# STM32H730xxQ register map
File version: 1.0
Registers are 32-bit, read-write, reset 0x0 unless marked. A register's access mark holds for its fields unless they carry their own. Offsets are from the block's base; [hi:lo] are bit positions; {n}, {i} and the like mark numbered series; 'fields as' and 'values as' point back to an identical list.

## FMC_Bank1E_R — Flexible Memory Controller Bank1E
Base 0x52004104
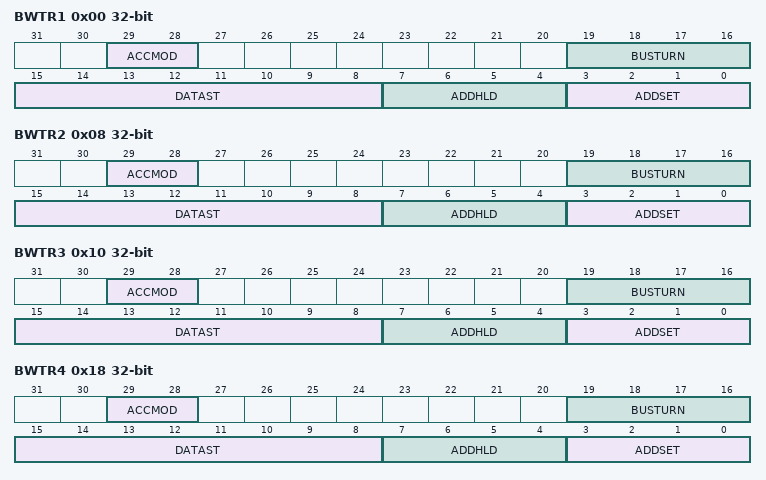
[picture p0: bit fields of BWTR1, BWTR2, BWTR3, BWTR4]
0x00 BWTR1 — NOR/PSRAM write timing registers
  [29:28] ACCMOD — ACCMOD[1:0] bits (Access mode)
  [19:16] BUSTURN — BUSTURN[3:0] bits (Bus turnaround phase duration)
  [15:8] DATAST — DATAST [3:0] bits (Data-phase duration)
  [7:4] ADDHLD — ADDHLD[3:0] bits (Address-hold phase duration)
  [3:0] ADDSET — ADDSET[3:0] bits (Address setup phase duration)
0x08 BWTR2 — NOR/PSRAM write timing registers
  fields as BWTR1
0x10 BWTR3 — NOR/PSRAM write timing registers
  fields as BWTR1
0x18 BWTR4 — NOR/PSRAM write timing registers
  fields as BWTR1

## FMC_Bank5_6_R — Flexible Memory Controller Bank5 and 6
Base 0x52004140
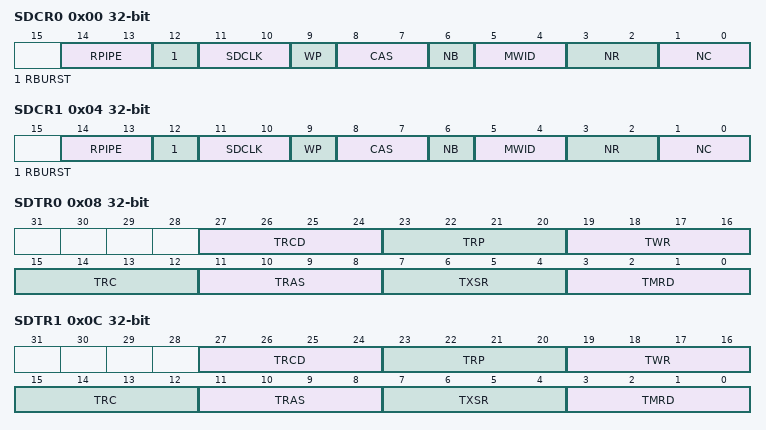
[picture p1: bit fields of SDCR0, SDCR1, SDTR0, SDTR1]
0x00 SDCR0 — SDRAM Control registers
  [14:13] RPIPE — Write protection
  [12] RBURST — Read burst
  [11:10] SDCLK — SDRAM clock configuration
  [9] WP — Write protection
  [8:7] CAS — CAS[1:0] bits (CAS latency)
  [6] NB — Number of internal bank
  [5:4] MWID — NR[1:0] bits (Number of row bits)
  [3:2] NR — NR[1:0] bits (Number of row bits)
  [1:0] NC — NC[1:0] bits (Number of column bits)
0x04 SDCR1 — SDRAM Control registers
  fields as SDCR0
0x08 SDTR0 — SDRAM Timing registers
  [27:24] TRCD — TRP[2:0] bits (Row to column delay)
  [23:20] TRP — TRP[2:0] bits (Row precharge delay)
  [19:16] TWR — TRC[2:0] bits (Write recovery delay)
  [15:12] TRC — TRC[2:0] bits (Row cycle delay)
  [11:8] TRAS — TRAS[3:0] bits (Self refresh time)
  [7:4] TXSR — TXSR[3:0] bits (Exit self refresh)
  [3:0] TMRD — TMRD[3:0] bits (Load mode register to active)
0x0C SDTR1 — SDRAM Timing registers
  fields as SDTR0
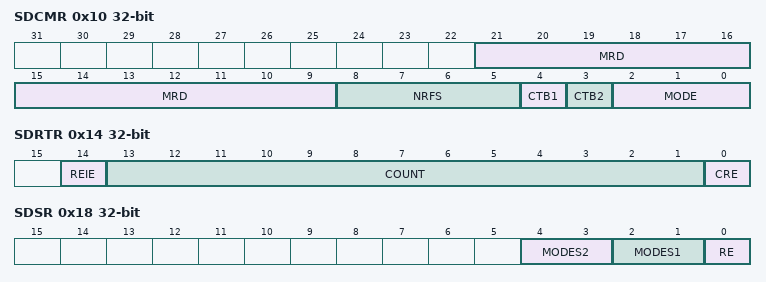
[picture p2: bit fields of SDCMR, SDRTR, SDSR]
0x10 SDCMR — SDRAM Command Mode register
  [21:9] MRD — MRD[12:0] bits (Mode register definition)
  [8:5] NRFS — NRFS[3:0] bits (Number of auto-refresh)
  [4] CTB1 — Command target 1
  [3] CTB2 — Command target 2
  [2:0] MODE — MODE[2:0] bits (Command mode)
0x14 SDRTR — SDRAM Refresh Timer register
  [14] REIE — RES interrupt enable
  [13:1] COUNT — COUNT[12:0] bits (Refresh timer count)
  [0] CRE — Clear refresh error flag
0x18 SDSR — SDRAM Status register
  [4:3] MODES2 — MODES2[1:0]bits (Status mode for bank 2)
  [2:1] MODES1 — MODES1[1:0]bits (Status mode for bank 1)
  [0] RE — Refresh error flag

## OCTOSPIM — OCTO Serial Peripheral Interface IO Manager
Base 0x5200B400
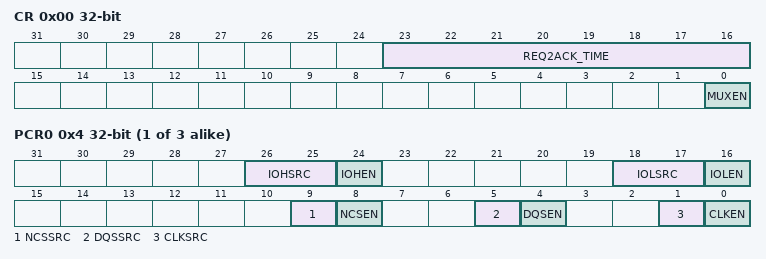
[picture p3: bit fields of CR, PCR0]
0x00 CR — OCTOSPI IO Manager Control register
  [23:16] REQ2ACK_TIME — REQ to ACK time
  [0] MUXEN — Multiplexed mode enable
{0x4+4i} PCR{i} (i=0..2) — OCTOSPI IO Manager Port[1:3] Configuration register
  [26:25] IOHSRC — IO[7:4] Source for Port n
  [24] IOHEN — IO[7:4] Enable for Port n
  [18:17] IOLSRC — IO[3:0] Source for Port n
  [16] IOLEN — IO[3:0] Enable for Port n
  [9] NCSSRC — nCS Source for Port n
  [8] NCSEN — nCS Enable for Port n
  [5] DQSSRC — DQS Source for Port n
  [4] DQSEN — DQS Enable for Port n
  [1] CLKSRC — CLK/CLKn Source for Port n
  [0] CLKEN — CLK/CLKn Enable for Port n

## OTFDEC1
Base 0x5200B800
Same registers: OTFDEC2 0x5200BC00
0x00 CR
  [0] ENC — Encryption mode bit
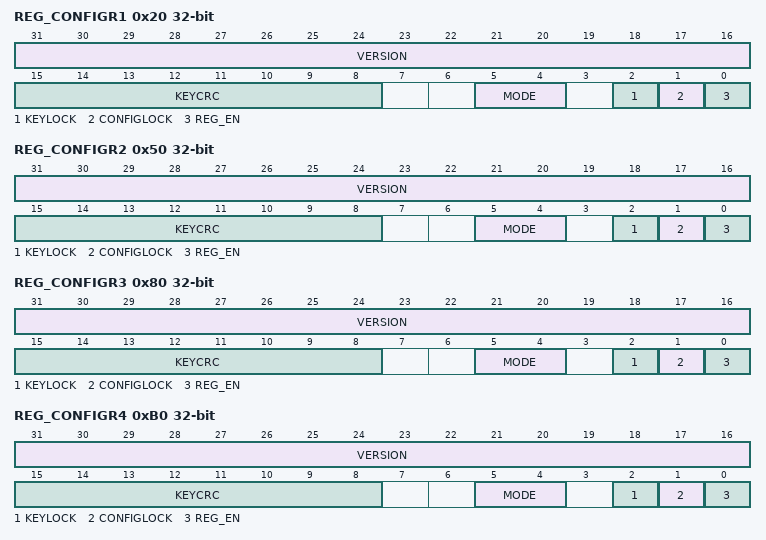
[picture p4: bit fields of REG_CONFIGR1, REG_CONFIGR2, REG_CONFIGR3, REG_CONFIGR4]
0x20 REG_CONFIGR1
  [31:16] VERSION — Region firmware version
  [15:8] KEYCRC — Region key 8-bit CRC
  [5:4] MODE — Region operating mode
  [2] KEYLOCK — Region key lock
  [1] CONFIGLOCK — Region config lock
  [0] REG_EN — Region on-the-fly decryption enable
0x24 REG_START_ADDR1
  [31:0] REG_START_ADDR — Region AHB start address
0x28 REG_END_ADDR1
  [31:0] REG_END_ADDR — Region AHB end address
0x2C REG_NONCER01
  [31:0] REG_NONCER0 — Region Nonce Register (LSB nonce[31:0])
0x30 REG_NONCER1
  [31:0] REG_NONCER1 — Region Nonce Register (MSB nonce[63:32])
{0x4+0x30*i} REG_KEYR{i:02} (i=1..4)
  [31:0] REG_KEYR0 — Region Key Register (LSB key[31:0])
{0x4+0x34*i} REG_KEYR{i} (i=1..3)
  [31:0] REG_KEYR{i} — Region Key Register (key[{32i+31}:{32i}])
0x3C REG_KEYR21
  [31:0] REG_KEYR2 — Region Key Register (key[95:64])
0x40 REG_KEYR31
  [31:0] REG_KEYR3 — Region Key Register (key[127:96])
0x50 REG_CONFIGR2
  fields as REG_CONFIGR1
0x54 REG_START_ADDR2
  [31:0] REG_START_ADDR — Region AHB start address
0x58 REG_END_ADDR2
  [31:0] REG_END_ADDR — Region AHB end address
0x5C REG_NONCER02
  [31:0] REG_NONCER0 — Region Nonce Register (LSB nonce[31:0])
0x60 REG_NONCER12
  [31:0] REG_NONCER1 — Region Nonce Register (MSB nonce[63:32])
0x68 REG_KEYR12
  [31:0] REG_KEYR1 — Region Key Register (key[63:32])
0x70 REG_KEYR32
  [31:0] REG_KEYR3 — Region Key Register (key[127:96])
0x80 REG_CONFIGR3
  fields as REG_CONFIGR1
0x84 REG_START_ADDR3
  [31:0] REG_START_ADDR — Region AHB start address
0x88 REG_END_ADDR3
  [31:0] REG_END_ADDR — Region AHB end address
0x8C REG_NONCER03
  [31:0] REG_NONCER0 — Region Nonce Register (LSB nonce[31:0])
0x90 REG_NONCER13
  [31:0] REG_NONCER1 — Region Nonce Register (MSB nonce[63:32])
0x98 REG_KEYR13
  [31:0] REG_KEYR1 — Region Key Register (key[63:32])
0x9C REG_KEYR23
  [31:0] REG_KEYR2 — Region Key Register (key[95:64])
0xB0 REG_CONFIGR4
  fields as REG_CONFIGR1
0xB4 REG_START_ADDR4
  [31:0] REG_START_ADDR — Region AHB start address
0xB8 REG_END_ADDR4
  [31:0] REG_END_ADDR — Region AHB end address
0xBC REG_NONCER04
  [31:0] REG_NONCER0 — Region Nonce Register (LSB nonce[31:0])
0xC0 REG_NONCER14
  [31:0] REG_NONCER1 — Region Nonce Register (MSB nonce[63:32])
0xC8 REG_KEYR14
  [31:0] REG_KEYR1 — Region Key Register (key[63:32])
0xCC REG_KEYR24
  [31:0] REG_KEYR2 — Region Key Register (key[95:64])
0xD0 REG_KEYR34
  [31:0] REG_KEYR3 — Region Key Register (key[127:96])
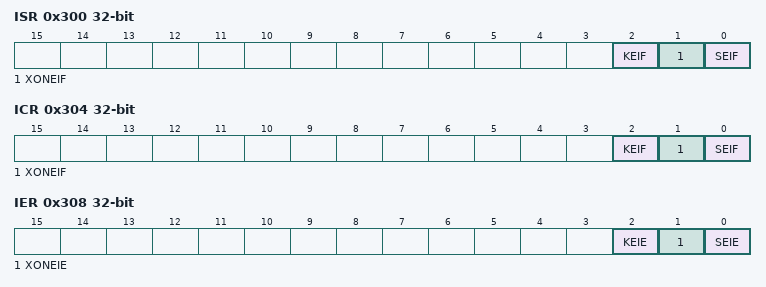
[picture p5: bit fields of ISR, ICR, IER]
0x300 ISR
  [2] KEIF — Key Error Interrupt Flag status bit before enable (mask)
  [1] XONEIF — Execute-only Error Interrupt Flag status bit before enable (mask)
  [0] SEIF — Security Error Interrupt Flag status bit before enable (mask)
0x304 ICR
  [2] KEIF — Key Error Interrupt Flag clear bit
  [1] XONEIF — Execute-only Error Interrupt Flag clear bit
  [0] SEIF — Security Error Interrupt Flag clear bit
0x308 IER
  [2] KEIE
  [1] XONEIE — Execute-only Error Interrupt Enable bit
  [0] SEIE — Security Error Interrupt Enable bit
0x3EC HWCFGR2
0x3F0 HWCFGR1
0x3F4 VERR
0x3F8 IPIDR
0x3FC SIDR
